# LM3S5C56 register map
File version: 7944
Registers are 32-bit, read-write, no defined reset value unless marked. A register's access mark holds for its fields unless they carry their own. Offsets are from the block's base; [hi:lo] are bit positions; {n}, {i} and the like mark numbered series.

## SSI0 — Register map for SSI0 peripheral
Base 0x40008000; register names take the prefix SSI0
Same registers: SSI1 0x40009000 (register names take the prefix SSI1)
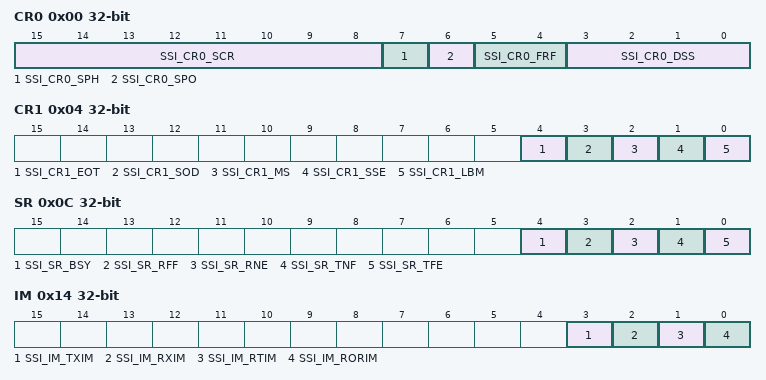
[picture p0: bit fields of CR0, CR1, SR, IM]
0x00 CR0 — SSI Control 0
  [15:8] SSI_CR0_SCR — SSI Serial Clock Rate
  [7] SSI_CR0_SPH — SSI Serial Clock Phase
  [6] SSI_CR0_SPO — SSI Serial Clock Polarity
  [5:4] SSI_CR0_FRF — SSI Frame Format Select
    0=SSI_CR0_FRF_MOTO (Freescale SPI Frame Format); 1=SSI_CR0_FRF_TI (Texas Instruments Synchronous Serial Frame Format); 2=SSI_CR0_FRF_NMW (MICROWIRE Frame Format)
  [3:0] SSI_CR0_DSS — SSI Data Size Select
    {v}={v+1}-bit data (v=3..15)
0x04 CR1 — SSI Control 1
  [4] SSI_CR1_EOT — End of Transmission
  [3] SSI_CR1_SOD — SSI Slave Mode Output Disable
  [2] SSI_CR1_MS — SSI Master/Slave Select
  [1] SSI_CR1_SSE — SSI Synchronous Serial Port Enable
  [0] SSI_CR1_LBM — SSI Loopback Mode
0x08 DR — SSI Data
  [15:0] SSI_DR_DATA — SSI Receive/Transmit Data
0x0C SR — SSI Status
  [4] SSI_SR_BSY — SSI Busy Bit
  [3] SSI_SR_RFF — SSI Receive FIFO Full
  [2] SSI_SR_RNE — SSI Receive FIFO Not Empty
  [1] SSI_SR_TNF — SSI Transmit FIFO Not Full
  [0] SSI_SR_TFE — SSI Transmit FIFO Empty
0x10 CPSR — SSI Clock Prescale
  [7:0] SSI_CPSR_CPSDVSR — SSI Clock Prescale Divisor
0x14 IM — SSI Interrupt Mask
  [3] SSI_IM_TXIM — SSI Transmit FIFO Interrupt Mask
  [2] SSI_IM_RXIM — SSI Receive FIFO Interrupt Mask
  [1] SSI_IM_RTIM — SSI Receive Time-Out Interrupt Mask
  [0] SSI_IM_RORIM — SSI Receive Overrun Interrupt Mask
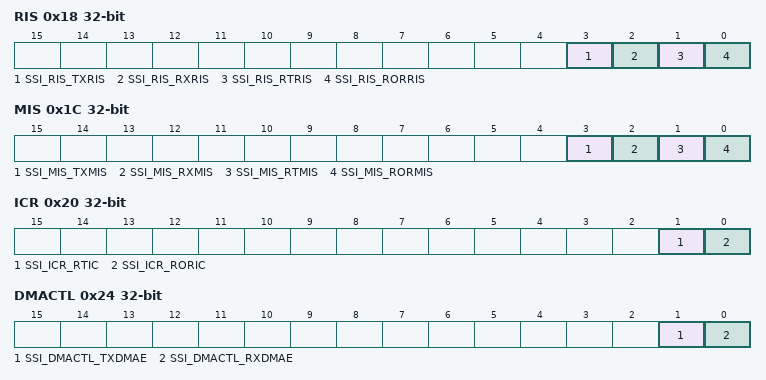
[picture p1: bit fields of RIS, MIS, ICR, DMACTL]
0x18 RIS — SSI Raw Interrupt Status
  [3] SSI_RIS_TXRIS — SSI Transmit FIFO Raw Interrupt Status
  [2] SSI_RIS_RXRIS — SSI Receive FIFO Raw Interrupt Status
  [1] SSI_RIS_RTRIS — SSI Receive Time-Out Raw Interrupt Status
  [0] SSI_RIS_RORRIS — SSI Receive Overrun Raw Interrupt Status
0x1C MIS — SSI Masked Interrupt Status
  [3] SSI_MIS_TXMIS — SSI Transmit FIFO Masked Interrupt Status
  [2] SSI_MIS_RXMIS — SSI Receive FIFO Masked Interrupt Status
  [1] SSI_MIS_RTMIS — SSI Receive Time-Out Masked Interrupt Status
  [0] SSI_MIS_RORMIS — SSI Receive Overrun Masked Interrupt Status
0x20 ICR wo — SSI Interrupt Clear
  [1] SSI_ICR_RTIC — SSI Receive Time-Out Interrupt Clear
  [0] SSI_ICR_RORIC — SSI Receive Overrun Interrupt Clear
0x24 DMACTL — SSI DMA Control
  [1] SSI_DMACTL_TXDMAE — Transmit DMA Enable
  [0] SSI_DMACTL_RXDMAE — Receive DMA Enable

## I2C0 — Register map for I2C0 peripheral
Base 0x40020000; register names take the prefix I2C0
Same registers: I2C1 0x40021000 (register names take the prefix I2C1)
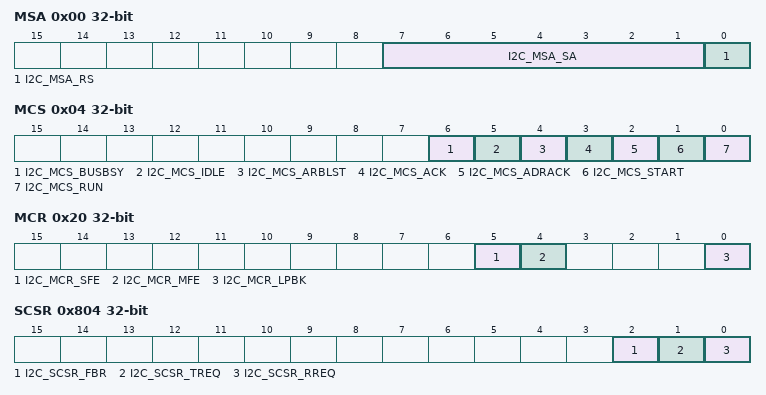
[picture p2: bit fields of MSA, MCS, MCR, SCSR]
0x00 MSA — I2C Master Slave Address
  [7:1] I2C_MSA_SA — I2C Slave Address
  [0] I2C_MSA_RS — Receive not send
0x04 MCS — I2C Master Control/Status
  [6] I2C_MCS_BUSBSY — Bus Busy
  [5] I2C_MCS_IDLE — I2C Idle
  [4] I2C_MCS_ARBLST — Arbitration Lost
  [3] I2C_MCS_ACK — Data Acknowledge Enable
  [2] I2C_MCS_ADRACK — Acknowledge Address
  [1] I2C_MCS_START — Generate START
  [0] I2C_MCS_RUN — I2C Master Enable
0x04 MCS (I2C0_ALT view) — I2C Master Control/Status
  [3] I2C_MCS_DATACK — Acknowledge Data
  [2] I2C_MCS_STOP — Generate STOP
  [1] I2C_MCS_ERROR — Error
  [0] I2C_MCS_BUSY — I2C Busy
0x08 MDR — I2C Master Data
  [7:0] I2C_MDR_DATA — Data Transferred
0x0C MTPR — I2C Master Timer Period
  [6:0] I2C_MTPR_TPR — SCL Clock Period
0x10 MIMR — I2C Master Interrupt Mask
  [0] I2C_MIMR_IM — Interrupt Mask
0x14 MRIS — I2C Master Raw Interrupt Status
  [0] I2C_MRIS_RIS — Raw Interrupt Status
0x18 MMIS — I2C Master Masked Interrupt Status
  [0] I2C_MMIS_MIS — Masked Interrupt Status
0x1C MICR wo — I2C Master Interrupt Clear
  [0] I2C_MICR_IC — Interrupt Clear
0x20 MCR — I2C Master Configuration
  [5] I2C_MCR_SFE — I2C Slave Function Enable
  [4] I2C_MCR_MFE — I2C Master Function Enable
  [0] I2C_MCR_LPBK — I2C Loopback
0x800 SOAR — I2C Slave Own Address
  [6:0] I2C_SOAR_OAR
0x804 SCSR — I2C Slave Control/Status
  [2] I2C_SCSR_FBR — First Byte Received
  [1] I2C_SCSR_TREQ — Transmit Request
  [0] I2C_SCSR_RREQ — Receive Request
0x804 SCSR (I2C0_ALT view) — I2C Slave Control/Status
  [0] I2C_SCSR_DA — Device Active
0x808 SDR — I2C Slave Data
  [7:0] I2C_SDR_DATA — Data for Transfer
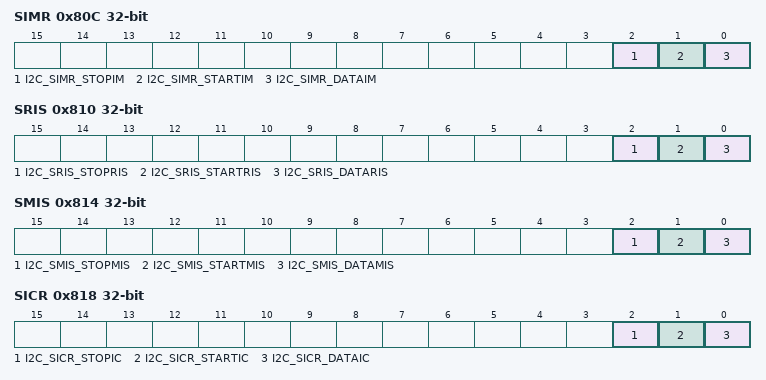
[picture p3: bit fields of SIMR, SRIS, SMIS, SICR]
0x80C SIMR — I2C Slave Interrupt Mask
  [2] I2C_SIMR_STOPIM — Stop Condition Interrupt Mask
  [1] I2C_SIMR_STARTIM — Start Condition Interrupt Mask
  [0] I2C_SIMR_DATAIM — Data Interrupt Mask
0x810 SRIS — I2C Slave Raw Interrupt Status
  [2] I2C_SRIS_STOPRIS — Stop Condition Raw Interrupt Status
  [1] I2C_SRIS_STARTRIS — Start Condition Raw Interrupt Status
  [0] I2C_SRIS_DATARIS — Data Raw Interrupt Status
0x814 SMIS — I2C Slave Masked Interrupt Status
  [2] I2C_SMIS_STOPMIS — Stop Condition Masked Interrupt Status
  [1] I2C_SMIS_STARTMIS — Start Condition Masked Interrupt Status
  [0] I2C_SMIS_DATAMIS — Data Masked Interrupt Status
0x818 SICR wo — I2C Slave Interrupt Clear
  [2] I2C_SICR_STOPIC — Stop Condition Interrupt Clear
  [1] I2C_SICR_STARTIC — Start Condition Interrupt Clear
  [0] I2C_SICR_DATAIC — Data Interrupt Clear
